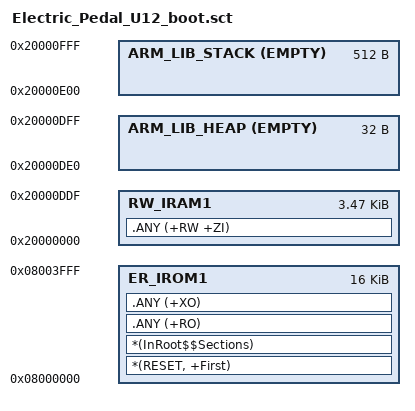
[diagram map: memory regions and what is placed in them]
LR_IROM1 0x08000000 0x00004000  {
  ER_IROM1 0x08000000 0x00004000  {
    *(RESET, +First)
    *(InRoot$$Sections)
    .ANY (+RO)
    .ANY (+XO)
  }
  RW_IRAM1 0x20000000 0x00000DE0  {
    .ANY (+RW +ZI)
  }
  ARM_LIB_HEAP 0x20000DE0 EMPTY 0x00000020  { }
  ARM_LIB_STACK 0x20001000 EMPTY -0x00000200 { }
}
